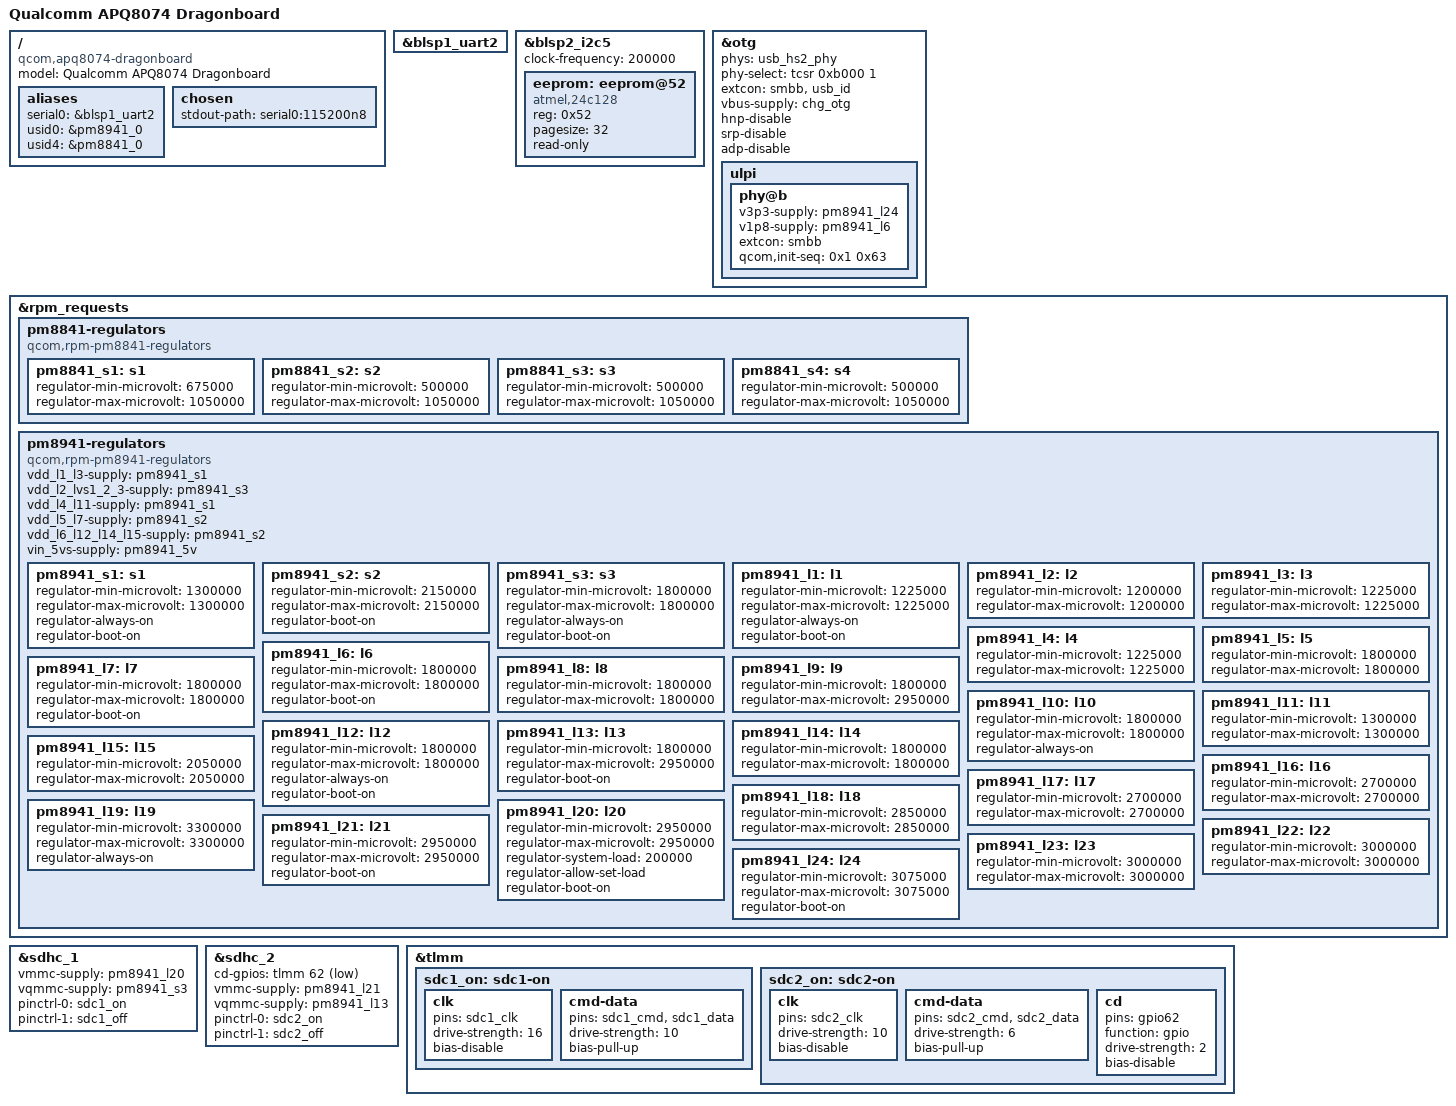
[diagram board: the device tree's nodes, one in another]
// SPDX-License-Identifier: GPL-2.0
#include <dt-bindings/gpio/gpio.h>
#include "qcom-msm8974.dtsi"
#include "qcom-pm8841.dtsi"
#include "qcom-pm8941.dtsi"

/ {
	model = "Qualcomm APQ8074 Dragonboard";
	compatible = "qcom,apq8074-dragonboard", "qcom,apq8074";

	aliases {
		serial0 = &blsp1_uart2;
		usid0 = &pm8941_0;
		usid4 = &pm8841_0;
	};

	chosen {
		stdout-path = "serial0:115200n8";
	};
};

&blsp1_uart2 {
	status = "okay";
};

&blsp2_i2c5 {
	status = "okay";
	clock-frequency = <200000>;

	eeprom: eeprom@52 {
		compatible = "atmel,24c128";
		reg = <0x52>;
		pagesize = <32>;
		read-only;
	};
};

&otg {
	status = "okay";

	phys = <&usb_hs2_phy>;
	phy-select = <&tcsr 0xb000 1>;
	extcon = <&smbb>, <&usb_id>;
	vbus-supply = <&chg_otg>;
	hnp-disable;
	srp-disable;
	adp-disable;

	ulpi {
		phy@b {
			status = "okay";
			v3p3-supply = <&pm8941_l24>;
			v1p8-supply = <&pm8941_l6>;
			extcon = <&smbb>;
			qcom,init-seq = /bits/ 8 <0x1 0x63>;
		};
	};
};

&rpm_requests {
	pm8841-regulators {
		compatible = "qcom,rpm-pm8841-regulators";

		pm8841_s1: s1 {
			regulator-min-microvolt = <675000>;
			regulator-max-microvolt = <1050000>;
		};

		pm8841_s2: s2 {
			regulator-min-microvolt = <500000>;
			regulator-max-microvolt = <1050000>;
		};

		pm8841_s3: s3 {
			regulator-min-microvolt = <500000>;
			regulator-max-microvolt = <1050000>;
		};

		pm8841_s4: s4 {
			regulator-min-microvolt = <500000>;
			regulator-max-microvolt = <1050000>;
		};
	};

	pm8941-regulators {
		compatible = "qcom,rpm-pm8941-regulators";

		vdd_l1_l3-supply = <&pm8941_s1>;
		vdd_l2_lvs1_2_3-supply = <&pm8941_s3>;
		vdd_l4_l11-supply = <&pm8941_s1>;
		vdd_l5_l7-supply = <&pm8941_s2>;
		vdd_l6_l12_l14_l15-supply = <&pm8941_s2>;
		vin_5vs-supply = <&pm8941_5v>;

		pm8941_s1: s1 {
			regulator-min-microvolt = <1300000>;
			regulator-max-microvolt = <1300000>;
			regulator-always-on;
			regulator-boot-on;
		};

		pm8941_s2: s2 {
			regulator-min-microvolt = <2150000>;
			regulator-max-microvolt = <2150000>;
			regulator-boot-on;
		};

		pm8941_s3: s3 {
			regulator-min-microvolt = <1800000>;
			regulator-max-microvolt = <1800000>;
			regulator-always-on;
			regulator-boot-on;
		};

		pm8941_l1: l1 {
			regulator-min-microvolt = <1225000>;
			regulator-max-microvolt = <1225000>;
			regulator-always-on;
			regulator-boot-on;
		};

		pm8941_l2: l2 {
			regulator-min-microvolt = <1200000>;
			regulator-max-microvolt = <1200000>;
		};

		pm8941_l3: l3 {
			regulator-min-microvolt = <1225000>;
			regulator-max-microvolt = <1225000>;
		};

		pm8941_l4: l4 {
			regulator-min-microvolt = <1225000>;
			regulator-max-microvolt = <1225000>;
		};

		pm8941_l5: l5 {
			regulator-min-microvolt = <1800000>;
			regulator-max-microvolt = <1800000>;
		};

		pm8941_l6: l6 {
			regulator-min-microvolt = <1800000>;
			regulator-max-microvolt = <1800000>;
			regulator-boot-on;
		};

		pm8941_l7: l7 {
			regulator-min-microvolt = <1800000>;
			regulator-max-microvolt = <1800000>;
			regulator-boot-on;
		};

		pm8941_l8: l8 {
			regulator-min-microvolt = <1800000>;
			regulator-max-microvolt = <1800000>;
		};

		pm8941_l9: l9 {
			regulator-min-microvolt = <1800000>;
			regulator-max-microvolt = <2950000>;
		};

		pm8941_l10: l10 {
			regulator-min-microvolt = <1800000>;
			regulator-max-microvolt = <1800000>;
			regulator-always-on;
		};

		pm8941_l11: l11 {
			regulator-min-microvolt = <1300000>;
			regulator-max-microvolt = <1300000>;
		};

		pm8941_l12: l12 {
			regulator-min-microvolt = <1800000>;
			regulator-max-microvolt = <1800000>;
			regulator-always-on;
			regulator-boot-on;
		};

		pm8941_l13: l13 {
			regulator-min-microvolt = <1800000>;
			regulator-max-microvolt = <2950000>;
			regulator-boot-on;
		};

		pm8941_l14: l14 {
			regulator-min-microvolt = <1800000>;
			regulator-max-microvolt = <1800000>;
		};

		pm8941_l15: l15 {
			regulator-min-microvolt = <2050000>;
			regulator-max-microvolt = <2050000>;
		};

		pm8941_l16: l16 {
			regulator-min-microvolt = <2700000>;
			regulator-max-microvolt = <2700000>;
		};

		pm8941_l17: l17 {
			regulator-min-microvolt = <2700000>;
			regulator-max-microvolt = <2700000>;
		};

		pm8941_l18: l18 {
			regulator-min-microvolt = <2850000>;
			regulator-max-microvolt = <2850000>;
		};

		pm8941_l19: l19 {
			regulator-min-microvolt = <3300000>;
			regulator-max-microvolt = <3300000>;
			regulator-always-on;
		};

		pm8941_l20: l20 {
			regulator-min-microvolt = <2950000>;
			regulator-max-microvolt = <2950000>;
			regulator-system-load = <200000>;
			regulator-allow-set-load;
			regulator-boot-on;
		};

		pm8941_l21: l21 {
			regulator-min-microvolt = <2950000>;
			regulator-max-microvolt = <2950000>;
			regulator-boot-on;
		};

		pm8941_l22: l22 {
			regulator-min-microvolt = <3000000>;
			regulator-max-microvolt = <3000000>;
		};

		pm8941_l23: l23 {
			regulator-min-microvolt = <3000000>;
			regulator-max-microvolt = <3000000>;
		};

		pm8941_l24: l24 {
			regulator-min-microvolt = <3075000>;
			regulator-max-microvolt = <3075000>;
			regulator-boot-on;
		};
	};
};

&sdhc_1 {
	status = "okay";

	vmmc-supply = <&pm8941_l20>;
	vqmmc-supply = <&pm8941_s3>;

	pinctrl-names = "default", "sleep";
	pinctrl-0 = <&sdc1_on>;
	pinctrl-1 = <&sdc1_off>;
};

&sdhc_2 {
	status = "okay";

	cd-gpios = <&tlmm 62 GPIO_ACTIVE_LOW>;
	vmmc-supply = <&pm8941_l21>;
	vqmmc-supply = <&pm8941_l13>;

	pinctrl-names = "default", "sleep";
	pinctrl-0 = <&sdc2_on>;
	pinctrl-1 = <&sdc2_off>;
};

&tlmm {
	sdc1_on: sdc1-on {
		clk {
			pins = "sdc1_clk";
			drive-strength = <16>;
			bias-disable;
		};

		cmd-data {
			pins = "sdc1_cmd", "sdc1_data";
			drive-strength = <10>;
			bias-pull-up;
		};
	};

	sdc2_on: sdc2-on {
		clk {
			pins = "sdc2_clk";
			drive-strength = <10>;
			bias-disable;
		};

		cmd-data {
			pins = "sdc2_cmd", "sdc2_data";
			drive-strength = <6>;
			bias-pull-up;
		};

		cd {
			pins = "gpio62";
			function = "gpio";
			drive-strength = <2>;
			bias-disable;
		};
	};
};
